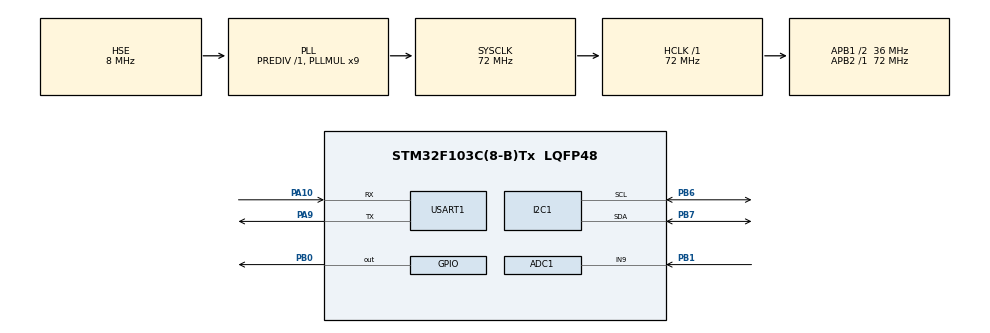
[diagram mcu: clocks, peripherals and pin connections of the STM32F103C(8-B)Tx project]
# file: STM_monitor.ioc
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ADC1.Channel-0\#ChannelRegularConversion=ADC_CHANNEL_9
ADC1.ContinuousConvMode=ENABLE
ADC1.NbrOfConversion=1
ADC1.NbrOfConversionFlag=1
ADC1.Rank-0\#ChannelRegularConversion=1
ADC1.SamplingTime-0\#ChannelRegularConversion=ADC_SAMPLETIME_1CYCLE_5
ADC1.master=1
Dma.ADC1.0.Direction=DMA_PERIPH_TO_MEMORY
Dma.ADC1.0.Instance=DMA1_Channel1
Dma.ADC1.0.MemDataAlignment=DMA_MDATAALIGN_HALFWORD
Dma.ADC1.0.MemInc=DMA_MINC_ENABLE
Dma.ADC1.0.Mode=DMA_CIRCULAR
Dma.ADC1.0.PeriphDataAlignment=DMA_PDATAALIGN_HALFWORD
Dma.ADC1.0.PeriphInc=DMA_PINC_DISABLE
Dma.ADC1.0.Priority=DMA_PRIORITY_MEDIUM
Dma.Request0=ADC1
FREERTOS.Tasks01=defaultTask,24,128,StartDefaultTask,Default,NULL,Dynamic,NULL,NULL
FREERTOS.configTOTAL_HEAP_SIZE=10240
FREERTOS.configUSE_NEWLIB_REENTRANT=0
Mcu.Family=STM32F1
Mcu.Name=STM32F103C(8-B)Tx
Mcu.Package=LQFP48
NVIC.DMA1_Channel1_IRQn=true\:5\:0\:false\:false\:true\:true\:false\:true\:true
NVIC.PriorityGroup=NVIC_PRIORITYGROUP_4
NVIC.TIM4_IRQn=true\:15\:0\:false\:false\:true\:false\:false\:true\:true
NVIC.TimeBase=TIM4_IRQn
NVIC.TimeBaseIP=TIM4
NVIC.USART1_IRQn=true\:5\:0\:false\:false\:true\:true\:true\:true\:true
PA0-WKUP.Mode=SYS_WakeUp0
PA0-WKUP.Signal=SYS_WKUP
PA10.Mode=Asynchronous
PA10.Signal=USART1_RX
PA13.Mode=Serial_Wire
PA13.Signal=SYS_JTMS-SWDIO
PA14.Mode=Serial_Wire
PA14.Signal=SYS_JTCK-SWCLK
PA9.Mode=Asynchronous
PA9.Signal=USART1_TX
PB0.GPIO_ModeDefaultOutputPP=GPIO_MODE_OUTPUT_OD
PB0.GPIO_PuPd=GPIO_NOPULL
PB0.GPIO_Speed=GPIO_SPEED_FREQ_HIGH
PB0.Signal=GPIO_Output
PB1.Signal=ADCx_IN9
PB6.Mode=I2C
PB6.Signal=I2C1_SCL
PB7.Mode=I2C
PB7.Signal=I2C1_SDA
PC14-OSC32_IN.Mode=LSE-External-Oscillator
PC14-OSC32_IN.Signal=RCC_OSC32_IN
PC15-OSC32_OUT.Mode=LSE-External-Oscillator
PC15-OSC32_OUT.Signal=RCC_OSC32_OUT
PD0-OSC_IN.Mode=HSE-External-Oscillator
PD0-OSC_IN.Signal=RCC_OSC_IN
PD1-OSC_OUT.Mode=HSE-External-Oscillator
PD1-OSC_OUT.Signal=RCC_OSC_OUT
ProjectManager.HeapSize=0x200
ProjectManager.StackSize=0x400
ProjectManager.TargetToolchain=STM32CubeIDE
RCC.ADCPresc=RCC_ADCPCLK2_DIV6
RCC.AHBFreq_Value=72000000
RCC.APB1CLKDivider=RCC_HCLK_DIV2
RCC.APB1Freq_Value=36000000
RCC.APB1TimFreq_Value=72000000
RCC.APB2Freq_Value=72000000
RCC.APB2TimFreq_Value=72000000
RCC.HCLKFreq_Value=72000000
RCC.PLLMUL=RCC_PLL_MUL9
RCC.PLLSourceVirtual=RCC_PLLSOURCE_HSE
RCC.SYSCLKFreq_VALUE=72000000
RCC.SYSCLKSource=RCC_SYSCLKSOURCE_PLLCLK
RCC.USBFreq_Value=72000000
SH.ADCx_IN9.0=ADC1_IN9,IN9
USART1.VirtualMode=VM_ASYNC
VP_FREERTOS_VS_CMSIS_V2.Mode=CMSIS_V2
VP_SYS_VS_tim4.Mode=TIM4
board=custom

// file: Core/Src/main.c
/* USER CODE BEGIN Header */
/**
  ******************************************************************************
  * @file           : main.c
  * @brief          : Main program body
  ******************************************************************************
  * @attention
  *
  * Copyright (c) 2026 STMicroelectronics.
  * All rights reserved.
  *
  * This software is licensed under terms that can be found in the LICENSE file
  * in the root directory of this software component.
  * If no LICENSE file comes with this software, it is provided AS-IS.
  *
  ******************************************************************************
  */
/* USER CODE END Header */
#include "main.h"
#include "cmsis_os.h"
#include "adc.h"
#include "dma.h"
#include "i2c.h"
#include "usart.h"
#include "gpio.h"

void SystemClock_Config(void);
void MX_FREERTOS_Init(void);

int main(void)
{

  /* MCU Configuration--------------------------------------------------------*/

  /* Reset of all peripherals, Initializes the Flash interface and the Systick. */
  HAL_Init();

  /* Configure the system clock */
  SystemClock_Config();

  /* Initialize all configured peripherals */
  MX_GPIO_Init();
  MX_DMA_Init();
  MX_ADC1_Init();
  MX_I2C1_Init();
  MX_USART1_UART_Init();

  /* Init scheduler */
  osKernelInitialize();  /* Call init function for freertos objects (in cmsis_os2.c) */
  MX_FREERTOS_Init();

  /* Start scheduler */
  osKernelStart();

  /* We should never get here as control is now taken by the scheduler */

  /* Infinite loop */
  while (1)
  {

  }
}

void SystemClock_Config(void)
{
  RCC_OscInitTypeDef RCC_OscInitStruct = {0};
  RCC_ClkInitTypeDef RCC_ClkInitStruct = {0};
  RCC_PeriphCLKInitTypeDef PeriphClkInit = {0};

  /** Initializes the RCC Oscillators according to the specified parameters
  * in the RCC_OscInitTypeDef structure.
  */
  RCC_OscInitStruct.OscillatorType = RCC_OSCILLATORTYPE_HSE;
  RCC_OscInitStruct.HSEState = RCC_HSE_ON;
  RCC_OscInitStruct.HSEPredivValue = RCC_HSE_PREDIV_DIV1;
  RCC_OscInitStruct.HSIState = RCC_HSI_ON;
  RCC_OscInitStruct.PLL.PLLState = RCC_PLL_ON;
  RCC_OscInitStruct.PLL.PLLSource = RCC_PLLSOURCE_HSE;
  RCC_OscInitStruct.PLL.PLLMUL = RCC_PLL_MUL9;
  if (HAL_RCC_OscConfig(&RCC_OscInitStruct) != HAL_OK)
  {
    Error_Handler();
  }

  /** Initializes the CPU, AHB and APB buses clocks
  */
  RCC_ClkInitStruct.ClockType = RCC_CLOCKTYPE_HCLK|RCC_CLOCKTYPE_SYSCLK
                              |RCC_CLOCKTYPE_PCLK1|RCC_CLOCKTYPE_PCLK2;
  RCC_ClkInitStruct.SYSCLKSource = RCC_SYSCLKSOURCE_PLLCLK;
  RCC_ClkInitStruct.AHBCLKDivider = RCC_SYSCLK_DIV1;
  RCC_ClkInitStruct.APB1CLKDivider = RCC_HCLK_DIV2;
  RCC_ClkInitStruct.APB2CLKDivider = RCC_HCLK_DIV1;

  if (HAL_RCC_ClockConfig(&RCC_ClkInitStruct, FLASH_LATENCY_2) != HAL_OK)
  {
    Error_Handler();
  }
  PeriphClkInit.PeriphClockSelection = RCC_PERIPHCLK_ADC;
  PeriphClkInit.AdcClockSelection = RCC_ADCPCLK2_DIV6;
  if (HAL_RCCEx_PeriphCLKConfig(&PeriphClkInit) != HAL_OK)
  {
    Error_Handler();
  }
}

void HAL_TIM_PeriodElapsedCallback(TIM_HandleTypeDef *htim)
{
  if (htim->Instance == TIM4)
  {
    HAL_IncTick();
  }
}

void Error_Handler(void)
{
  __disable_irq();
  while (1)
  {
  }
}

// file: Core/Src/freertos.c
/* USER CODE BEGIN Header */
/**
  ******************************************************************************
  * File Name          : freertos.c
  * Description        : Code for freertos applications
  ******************************************************************************
  * @attention
  *
  * Copyright (c) 2026 STMicroelectronics.
  * All rights reserved.
  *
  * This software is licensed under terms that can be found in the LICENSE file
  * in the root directory of this software component.
  * If no LICENSE file comes with this software, it is provided AS-IS.
  *
  ******************************************************************************
  */
/* USER CODE END Header */

#include "FreeRTOS.h"
#include "task.h"
#include "main.h"
#include "cmsis_os.h"

/* USER CODE BEGIN Includes */
#include "mySerial.h"
#include "OLED.h"
#include "db.h"
#include "main_task.h"
#include "temperature.h"
/* USER CODE END Includes */

/* Definitions for defaultTask */
osThreadId_t defaultTaskHandle;
const osThreadAttr_t defaultTask_attributes = {
  .name = "defaultTask",
  .stack_size = 128 * 4,
  .priority = (osPriority_t) osPriorityNormal,
};

void StartDefaultTask(void *argument);

void MX_FREERTOS_Init(void); /* (MISRA C 2004 rule 8.1) */

void MX_FREERTOS_Init(void) {

  /* Create the thread(s) */
  /* creation of defaultTask */
  defaultTaskHandle = osThreadNew(StartDefaultTask, NULL, &defaultTask_attributes);

  /* USER CODE BEGIN RTOS_THREADS */
  OLED_Init();
  mySerial_RTOS_Init();
  mySerial_init();

  DHT22_RTOS_Init();
  DB_RTOS_Init();
  main_task_RTOS_Init();
  /* USER CODE END RTOS_THREADS */

}

void StartDefaultTask(void *argument)
{
  for(;;)
  {
    osDelay(1);
  }
}
